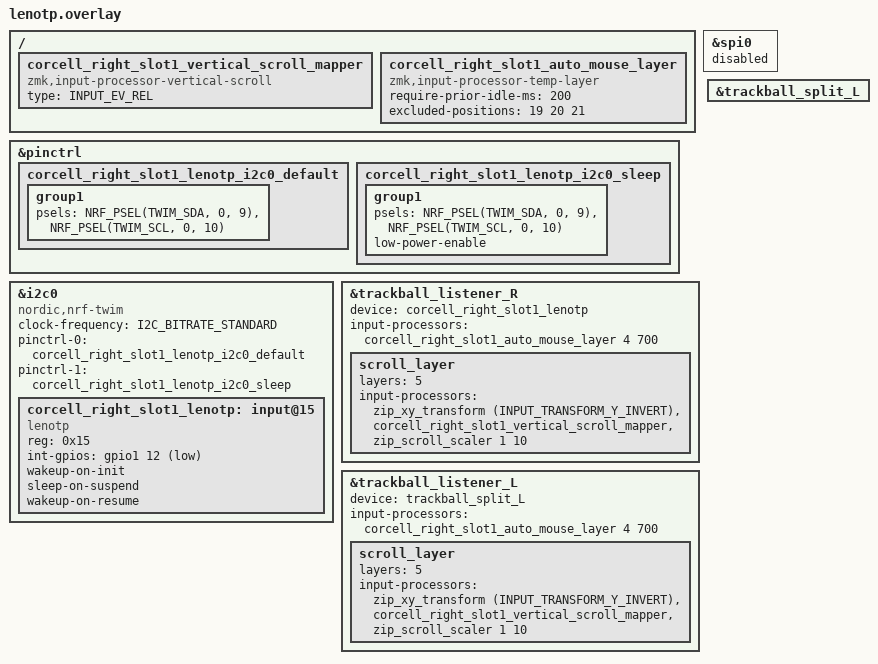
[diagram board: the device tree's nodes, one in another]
#include <dt-bindings/pinctrl/nrf-pinctrl.h>
#include <dt-bindings/zmk/input_transform.h>
#include <zephyr/dt-bindings/input/input-event-codes.h>
#include <zephyr/dt-bindings/i2c/i2c.h>
#include <input/processors.dtsi>

/*
 * lenoTP in FPC slot 1, in place of the PAW3222. The module keeps the
 * PAW's pinout, so the slot's nets are reused as:
 *
 *   FPC 1 NC   <- PAW NCS    (unused here)
 *   FPC 2 SCL  <- PAW SCLK   P0.10
 *   FPC 3 INT  <- PAW MOTION P1.12
 *   FPC 4 SDA  <- PAW SDIO   P0.09
 *   FPC 5 VCC
 *   FPC 6 GND
 *
 * i2c0 and spi0 are the same peripheral instance on the nRF52840
 * (both at 0x40003000), so spi0 has to go for this to work. That is fine
 * here: the lenoTP replaces the PAW rather than sitting beside it.
 */
&spi0 {
    status = "disabled";
};

&pinctrl {
    corcell_right_slot1_lenotp_i2c0_default: corcell_right_slot1_lenotp_i2c0_default {
        group1 {
            psels = <NRF_PSEL(TWIM_SDA, 0, 9)>,
                    <NRF_PSEL(TWIM_SCL, 0, 10)>;
        };
    };

    corcell_right_slot1_lenotp_i2c0_sleep: corcell_right_slot1_lenotp_i2c0_sleep {
        group1 {
            psels = <NRF_PSEL(TWIM_SDA, 0, 9)>,
                    <NRF_PSEL(TWIM_SCL, 0, 10)>;
            low-power-enable;
        };
    };
};

&i2c0 {
    compatible = "nordic,nrf-twim";
    status = "okay";
    /* New FPC: SCL/SDA each have an external 4.7k pull-up to 3V3.
     * Keep the existing conservative 100kHz rate for first bring-up. */
    clock-frequency = <I2C_BITRATE_STANDARD>;
    pinctrl-0 = <&corcell_right_slot1_lenotp_i2c0_default>;
    pinctrl-1 = <&corcell_right_slot1_lenotp_i2c0_sleep>;
    pinctrl-names = "default", "sleep";

    corcell_right_slot1_lenotp: input@15 {
        compatible = "lenotp";
        reg = <0x15>;
        status = "okay";
        /* External 10k pull-up on the FPC. */
        int-gpios = <&gpio1 12 GPIO_ACTIVE_LOW>;

        /*
         * Without this the driver's init sends no command at all, so a
         * module that powers up asleep never reports anything.
         *
         * Only Wake up (0x22 0x00 0x00 0x08) and Sleep are in the YDX-C09
         * datasheet, and the driver's lenotp_wakeup matches it byte for
         * byte. exit-idle-on-init is deliberately left off: the 0x25 ...
         * sequence behind it is undocumented for this part, and a NACK
         * there fails driver init outright.
         */
        wakeup-on-init;

        /* Let ZMK sleep actually save power on a dry-cell build. */
        sleep-on-suspend;
        wakeup-on-resume;
    };
};

/ {
    corcell_right_slot1_vertical_scroll_mapper: corcell_right_slot1_vertical_scroll_mapper {
        compatible = "zmk,input-processor-vertical-scroll";
        #input-processor-cells = <0>;
        type = <INPUT_EV_REL>;
    };

    corcell_right_slot1_auto_mouse_layer: corcell_right_slot1_auto_mouse_layer {
        compatible = "zmk,input-processor-temp-layer";
        #input-processor-cells = <2>;
        require-prior-idle-ms = <200>;
        excluded-positions = <19 20 21>;
    };
};

/*
 * No transform or scaler yet. The lenoTP reports on its own scale and its
 * mounting orientation has not been checked on hardware, so tune it once
 * with the driver's own invert-x / invert-y / swap-xy / x-divisor /
 * y-divisor rather than guessing here.
 */
&trackball_listener_R {
    status = "okay";
    device = <&corcell_right_slot1_lenotp>;
    input-processors =
        <&corcell_right_slot1_auto_mouse_layer 4 700>;

    scroll_layer {
        layers = <5>;
        input-processors =
            <&zip_xy_transform (INPUT_TRANSFORM_Y_INVERT)>,
            <&corcell_right_slot1_vertical_scroll_mapper>,
            <&zip_scroll_scaler 1 10>;
    };
};

/* Input relayed from the left half. */
&trackball_split_L {
    status = "okay";
};

&trackball_listener_L {
    status = "okay";
    device = <&trackball_split_L>;
    input-processors =
        <&corcell_right_slot1_auto_mouse_layer 4 700>;

    scroll_layer {
        layers = <5>;
        input-processors =
            <&zip_xy_transform (INPUT_TRANSFORM_Y_INVERT)>,
            <&corcell_right_slot1_vertical_scroll_mapper>,
            <&zip_scroll_scaler 1 10>;
    };
};
